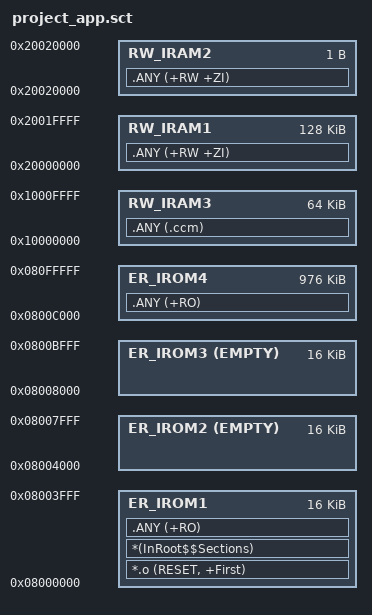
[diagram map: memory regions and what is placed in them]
; *************************************************************
; *** Scatter-Loading Description File generated by uVision ***
; *************************************************************

LR_IROM1 0x08000000 0x4000  {    ; load region size_region
  ER_IROM1 0x08000000 0x4000  {  ; load address = execution address
   *.o (RESET, +First)
   *(InRoot$$Sections)
   .ANY (+RO)
  }
  RW_IRAM1 0x20000000 0x20000  {  ; RW data
   .ANY (+RW +ZI)
  }
  RW_IRAM2 0x20020000 0x1  {
   .ANY (+RW +ZI)
  }  
  RW_IRAM3 0x10000000 0x10000  {
   .ANY (.ccm)
  }    
}
LR_IROM2 0x08004000 0x4000  {    ; load region size_region
  ER_IROM2 0x08004000 EMPTY 0x4000  {  ; load address = execution address
  }
}
LR_IROM3 0x08008000 0x4000  {    ; load region size_region
  ER_IROM3 0x08008000 EMPTY 0x4000  {  ; load address = execution address
  }
}
LR_IROM4 0x0800c000 0x100000-0xc000  {    ; load region size_region
  ER_IROM4 0x0800c000 0x100000-0xc000  {  ; load address = execution address
   .ANY (+RO)
  }
}


